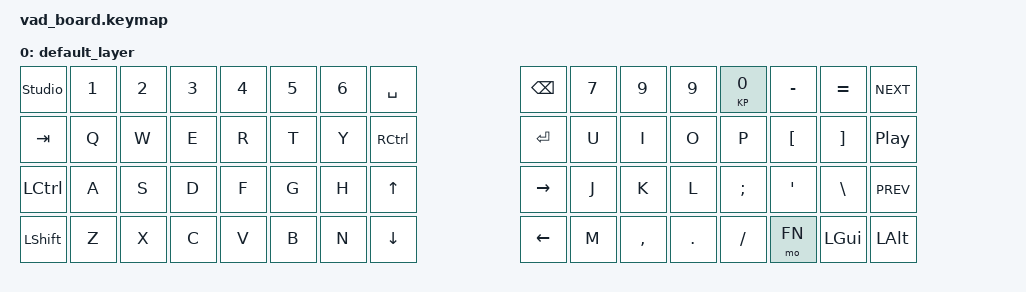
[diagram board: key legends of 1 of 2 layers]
/*
 * Copyright (c) 2020 The ZMK Contributors
 *
 * SPDX-License-Identifier: MIT
 */

#include <behaviors.dtsi>
#include <dt-bindings/zmk/keys.h>
#include <dt-bindings/zmk/bt.h>

#define DEFAULT 0
#define FN 1


//SPECIAL KEYS
#define m1_d &kp C_NEXT
#define m2_d &kp C_PP
#define m3_d &kp C_PREV


#define m1_fn &kp C_VOL_UP
#define m2_fn &kp C_MUTE
#define m3_fn &kp C_VOL_DN

/ {
        keymap {
                compatible = "zmk,keymap";

                default_layer {
// -----------------------------------------------------------------------------------------
// |      |  1  |  2  |  3  |  4  |  5  |  6  | SPC |    -    | BSPC |  7   |  8  |  9  |  0  |  -   |  =  |  m1  |
// | TAB  |  Q  |  W  |  E  |  R  |  T  |  Y  | CTRL|    -    | ENT  |  U   |  I  |  O  |  P  |  [   |  ]  |  m2  |
// | CTRL |  A  |  S  |  D  |  F  |  G  |  H  | UP  |    -    | RGT  |  J   |  K  |  L  |  ;  |  '   |  \  |  m3  |
// | SHFT |  Z  |  X  |  C  |  V  |  B  |  N  | DWN |    -    | LFT  |  M   |  ,  |  .  |  /  |  FN  | WIN | LALT |


                        bindings = <
   &studio_unlock    &kp N1  &kp N2  &kp N3  &kp N4  &kp N5  &kp N6  &kp SPACE                 &kp BSPC   &kp N7  &kp N9     &kp N9   &KP N0     &kp MINUS   &kp EQUAL  m1_d      
   &kp TAB   &kp Q   &kp W   &kp E   &kp R   &kp T   &kp Y   &kp RCTRL                 &kp ENTER  &kp U   &kp I      &kp O    &kp P      &kp LBKT    &kp RBKT   m2_d
   &kp LCTRL &kp A   &kp S   &kp D   &kp F   &kp G   &kp H   &kp UP                    &kp RIGHT  &kp J   &kp K      &kp L    &kp SEMI   &kp SQT     &kp BSLH   m3_d
   &kp LSHFT &kp Z   &kp X   &kp C   &kp V   &kp B   &kp N   &kp DOWN                  &kp LEFT   &kp M   &kp COMMA  &kp DOT  &kp FSLH   &mo FN      &kp LGUI   &kp LALT
                        >;
                };
                fn_layer {
// -----------------------------------------------------------------------------------------
// |      |   F1   |   F2   |   F3   |   F4   |   F5   |  F6 |     |    -    |      |  F8  |  F9 | F10 | F11 | F12  |PSCRN|    |
// |BT_CLR|BT_SEL 0|BT_SEL 1|BT_SEL 2|BT_SEL 3|BT_SEL 4|     |     |    -    |      |      |     |     |     |      |     |    |
// |      |        |        |        |        |        |     |     |    -    |      |      |     |     |     |      |     |    |
// |      |        |        |        |        |        |     |     |    -    |      |      |     |     |     |      |     |    |

                        bindings = <
   &trans      &kp F1        &kp F2        &kp F3        &kp F4        &kp F5        &kp F6       &kp F7   &kp F8   &kp F9   &kp F10   &kp F11   &kp F12   &kp PSCRN   m1_fn
   &bt BT_CLR  &bt BT_SEL 0  &bt BT_SEL 1  &bt BT_SEL 2  &bt BT_SEL 3  &bt BT_SEL 4  &trans       &trans   &trans   &trans   &trans    &trans    &trans    &trans      m2_fn
   &kp LSHFT   &trans        &trans        &trans        &trans        &trans        &trans       &trans   &trans   &trans   &trans    &trans    &trans    &trans      m3_fn
   &trans      &trans        &trans        &trans        &trans        &trans        &trans       &trans   &trans   &trans   &trans    &trans    &trans    &trans      &trans
                        >;
                };
        };
};
